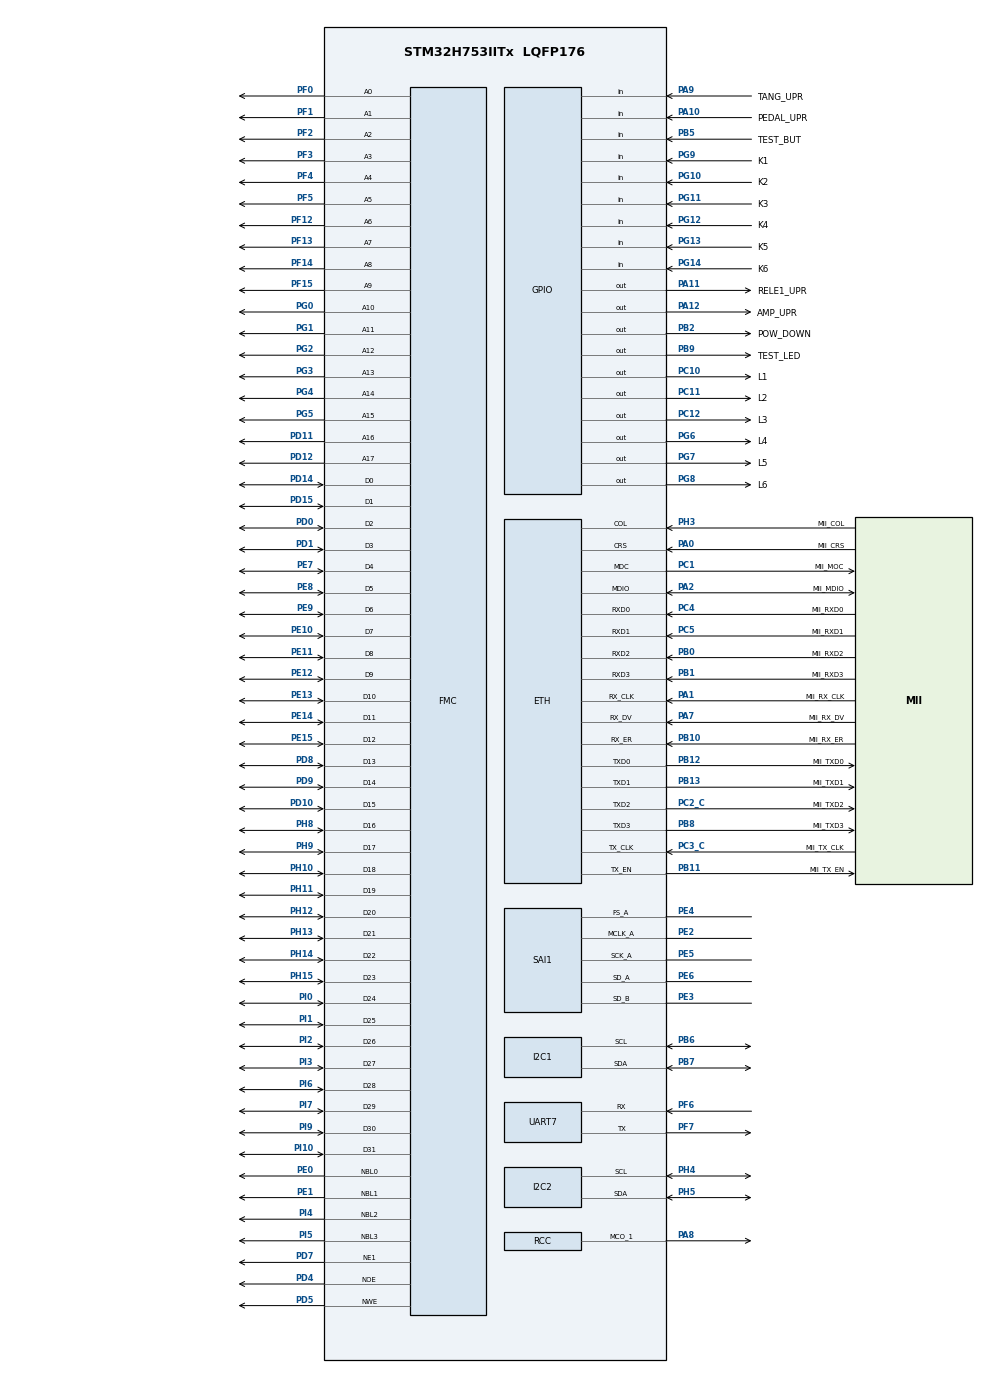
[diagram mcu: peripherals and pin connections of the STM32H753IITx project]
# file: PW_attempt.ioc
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CORTEX_M7.AccessPermission-Cortex_Memory_Protection_Unit_Region0_Settings=MPU_REGION_FULL_ACCESS
CORTEX_M7.AccessPermission-Cortex_Memory_Protection_Unit_Region1_Settings=MPU_REGION_FULL_ACCESS
CORTEX_M7.AccessPermission-Cortex_Memory_Protection_Unit_Region2_Settings=MPU_REGION_FULL_ACCESS
CORTEX_M7.BaseAddress-Cortex_Memory_Protection_Unit_Region0_Settings=30000000
CORTEX_M7.BaseAddress-Cortex_Memory_Protection_Unit_Region1_Settings=0x30000000
CORTEX_M7.BaseAddress-Cortex_Memory_Protection_Unit_Region2_Settings=0x30040000
CORTEX_M7.CPU_DCache=Enabled
CORTEX_M7.CPU_ICache=Enabled
CORTEX_M7.DisableExec-Cortex_Memory_Protection_Unit_Region0_Settings=MPU_INSTRUCTION_ACCESS_DISABLE
CORTEX_M7.DisableExec-Cortex_Memory_Protection_Unit_Region1_Settings=MPU_INSTRUCTION_ACCESS_DISABLE
CORTEX_M7.DisableExec-Cortex_Memory_Protection_Unit_Region2_Settings=MPU_INSTRUCTION_ACCESS_DISABLE
CORTEX_M7.Enable-Cortex_Memory_Protection_Unit_Region0_Settings=MPU_REGION_ENABLE
CORTEX_M7.Enable-Cortex_Memory_Protection_Unit_Region1_Settings=MPU_REGION_ENABLE
CORTEX_M7.Enable-Cortex_Memory_Protection_Unit_Region2_Settings=MPU_REGION_ENABLE
CORTEX_M7.IsBufferable-Cortex_Memory_Protection_Unit_Region0_Settings=MPU_ACCESS_NOT_BUFFERABLE
CORTEX_M7.IsBufferable-Cortex_Memory_Protection_Unit_Region1_Settings=MPU_ACCESS_BUFFERABLE
CORTEX_M7.IsCacheable-Cortex_Memory_Protection_Unit_Region1_Settings=MPU_ACCESS_NOT_CACHEABLE
CORTEX_M7.IsShareable-Cortex_Memory_Protection_Unit_Region0_Settings=MPU_ACCESS_NOT_SHAREABLE
CORTEX_M7.IsShareable-Cortex_Memory_Protection_Unit_Region1_Settings=MPU_ACCESS_SHAREABLE
CORTEX_M7.MPU_Control=MPU_PRIVILEGED_DEFAULT
CORTEX_M7.Size-Cortex_Memory_Protection_Unit_Region0_Settings=MPU_REGION_SIZE_256KB
CORTEX_M7.Size-Cortex_Memory_Protection_Unit_Region1_Settings=MPU_REGION_SIZE_256B
CORTEX_M7.Size-Cortex_Memory_Protection_Unit_Region2_Settings=MPU_REGION_SIZE_32KB
CORTEX_M7.TypeExtField-Cortex_Memory_Protection_Unit_Region0_Settings=MPU_TEX_LEVEL1
CORTEX_M7.TypeExtField-Cortex_Memory_Protection_Unit_Region2_Settings=MPU_TEX_LEVEL1
Dma.I2C1_RX.1.Direction=DMA_PERIPH_TO_MEMORY
Dma.I2C1_RX.1.EventEnable=DISABLE
Dma.I2C1_RX.1.FIFOMode=DMA_FIFOMODE_DISABLE
Dma.I2C1_RX.1.Instance=DMA2_Stream0
Dma.I2C1_RX.1.MemDataAlignment=DMA_MDATAALIGN_BYTE
Dma.I2C1_RX.1.MemInc=DMA_MINC_ENABLE
Dma.I2C1_RX.1.Mode=DMA_NORMAL
Dma.I2C1_RX.1.PeriphDataAlignment=DMA_PDATAALIGN_BYTE
Dma.I2C1_RX.1.PeriphInc=DMA_PINC_DISABLE
Dma.I2C1_RX.1.Polarity=HAL_DMAMUX_REQ_GEN_RISING
Dma.I2C1_RX.1.Priority=DMA_PRIORITY_HIGH
Dma.I2C1_RX.1.RequestNumber=1
Dma.I2C1_RX.1.SignalID=NONE
Dma.I2C1_RX.1.SyncEnable=DISABLE
Dma.I2C1_RX.1.SyncPolarity=HAL_DMAMUX_SYNC_NO_EVENT
Dma.I2C1_RX.1.SyncRequestNumber=1
Dma.I2C1_RX.1.SyncSignalID=NONE
Dma.I2C1_TX.2.Direction=DMA_MEMORY_TO_PERIPH
Dma.I2C1_TX.2.EventEnable=DISABLE
Dma.I2C1_TX.2.FIFOMode=DMA_FIFOMODE_DISABLE
Dma.I2C1_TX.2.Instance=DMA2_Stream1
Dma.I2C1_TX.2.MemDataAlignment=DMA_MDATAALIGN_BYTE
Dma.I2C1_TX.2.MemInc=DMA_MINC_ENABLE
Dma.I2C1_TX.2.Mode=DMA_NORMAL
Dma.I2C1_TX.2.PeriphDataAlignment=DMA_PDATAALIGN_BYTE
Dma.I2C1_TX.2.PeriphInc=DMA_PINC_DISABLE
Dma.I2C1_TX.2.Polarity=HAL_DMAMUX_REQ_GEN_RISING
Dma.I2C1_TX.2.Priority=DMA_PRIORITY_HIGH
Dma.I2C1_TX.2.RequestNumber=1
Dma.I2C1_TX.2.SignalID=NONE
Dma.I2C1_TX.2.SyncEnable=DISABLE
Dma.I2C1_TX.2.SyncPolarity=HAL_DMAMUX_SYNC_NO_EVENT
Dma.I2C1_TX.2.SyncRequestNumber=1
Dma.I2C1_TX.2.SyncSignalID=NONE
Dma.I2C2_RX.5.Direction=DMA_PERIPH_TO_MEMORY
Dma.I2C2_RX.5.EventEnable=DISABLE
Dma.I2C2_RX.5.FIFOMode=DMA_FIFOMODE_DISABLE
Dma.I2C2_RX.5.Instance=DMA1_Stream2
Dma.I2C2_RX.5.MemDataAlignment=DMA_MDATAALIGN_BYTE
Dma.I2C2_RX.5.MemInc=DMA_MINC_ENABLE
Dma.I2C2_RX.5.Mode=DMA_NORMAL
Dma.I2C2_RX.5.PeriphDataAlignment=DMA_PDATAALIGN_BYTE
Dma.I2C2_RX.5.PeriphInc=DMA_PINC_DISABLE
Dma.I2C2_RX.5.Polarity=HAL_DMAMUX_REQ_GEN_RISING
Dma.I2C2_RX.5.Priority=DMA_PRIORITY_LOW
Dma.I2C2_RX.5.RequestNumber=1
Dma.I2C2_RX.5.SignalID=NONE
Dma.I2C2_RX.5.SyncEnable=DISABLE
Dma.I2C2_RX.5.SyncPolarity=HAL_DMAMUX_SYNC_NO_EVENT
Dma.I2C2_RX.5.SyncRequestNumber=1
Dma.I2C2_RX.5.SyncSignalID=NONE
Dma.I2C2_TX.6.Direction=DMA_MEMORY_TO_PERIPH
Dma.I2C2_TX.6.EventEnable=DISABLE
Dma.I2C2_TX.6.FIFOMode=DMA_FIFOMODE_DISABLE
Dma.I2C2_TX.6.Instance=DMA1_Stream4
Dma.I2C2_TX.6.MemDataAlignment=DMA_MDATAALIGN_BYTE
Dma.I2C2_TX.6.MemInc=DMA_MINC_ENABLE
Dma.I2C2_TX.6.Mode=DMA_NORMAL
Dma.I2C2_TX.6.PeriphDataAlignment=DMA_PDATAALIGN_BYTE
Dma.I2C2_TX.6.PeriphInc=DMA_PINC_DISABLE
Dma.I2C2_TX.6.Polarity=HAL_DMAMUX_REQ_GEN_RISING
Dma.I2C2_TX.6.Priority=DMA_PRIORITY_LOW
Dma.I2C2_TX.6.RequestNumber=1
Dma.I2C2_TX.6.SignalID=NONE
Dma.I2C2_TX.6.SyncEnable=DISABLE
Dma.I2C2_TX.6.SyncPolarity=HAL_DMAMUX_SYNC_NO_EVENT
Dma.I2C2_TX.6.SyncRequestNumber=1
Dma.I2C2_TX.6.SyncSignalID=NONE
Dma.Request0=UART7_TX
Dma.Request1=I2C1_RX
Dma.Request2=I2C1_TX
Dma.Request3=SAI1_A
Dma.Request4=SAI1_B
Dma.Request5=I2C2_RX
Dma.Request6=I2C2_TX
Dma.SAI1_A.3.Direction=DMA_MEMORY_TO_PERIPH
Dma.SAI1_A.3.EventEnable=DISABLE
Dma.SAI1_A.3.FIFOMode=DMA_FIFOMODE_DISABLE
Dma.SAI1_A.3.Instance=DMA2_Stream3
Dma.SAI1_A.3.MemDataAlignment=DMA_MDATAALIGN_WORD
Dma.SAI1_A.3.MemInc=DMA_MINC_ENABLE
Dma.SAI1_A.3.Mode=DMA_NORMAL
Dma.SAI1_A.3.PeriphDataAlignment=DMA_PDATAALIGN_WORD
Dma.SAI1_A.3.PeriphInc=DMA_PINC_DISABLE
Dma.SAI1_A.3.Polarity=HAL_DMAMUX_REQ_GEN_RISING
Dma.SAI1_A.3.Priority=DMA_PRIORITY_LOW
Dma.SAI1_A.3.RequestNumber=1
Dma.SAI1_A.3.SignalID=NONE
Dma.SAI1_A.3.SyncEnable=DISABLE
Dma.SAI1_A.3.SyncPolarity=HAL_DMAMUX_SYNC_NO_EVENT
Dma.SAI1_A.3.SyncRequestNumber=1
Dma.SAI1_A.3.SyncSignalID=NONE
Dma.SAI1_B.4.Direction=DMA_PERIPH_TO_MEMORY
Dma.SAI1_B.4.EventEnable=DISABLE
Dma.SAI1_B.4.FIFOMode=DMA_FIFOMODE_DISABLE
Dma.SAI1_B.4.Instance=DMA2_Stream4
Dma.SAI1_B.4.MemDataAlignment=DMA_MDATAALIGN_WORD
Dma.SAI1_B.4.MemInc=DMA_MINC_ENABLE
Dma.SAI1_B.4.Mode=DMA_NORMAL
Dma.SAI1_B.4.PeriphDataAlignment=DMA_PDATAALIGN_WORD
Dma.SAI1_B.4.PeriphInc=DMA_PINC_DISABLE
Dma.SAI1_B.4.Polarity=HAL_DMAMUX_REQ_GEN_RISING
Dma.SAI1_B.4.Priority=DMA_PRIORITY_LOW
Dma.SAI1_B.4.RequestNumber=1
Dma.SAI1_B.4.SignalID=NONE
Dma.SAI1_B.4.SyncEnable=DISABLE
Dma.SAI1_B.4.SyncPolarity=HAL_DMAMUX_SYNC_NO_EVENT
Dma.SAI1_B.4.SyncRequestNumber=1
Dma.SAI1_B.4.SyncSignalID=NONE
Dma.UART7_TX.0.Direction=DMA_MEMORY_TO_PERIPH
Dma.UART7_TX.0.EventEnable=DISABLE
Dma.UART7_TX.0.FIFOMode=DMA_FIFOMODE_DISABLE
Dma.UART7_TX.0.Instance=DMA1_Stream1
Dma.UART7_TX.0.MemDataAlignment=DMA_MDATAALIGN_BYTE
Dma.UART7_TX.0.MemInc=DMA_MINC_ENABLE
Dma.UART7_TX.0.Mode=DMA_NORMAL
Dma.UART7_TX.0.PeriphDataAlignment=DMA_PDATAALIGN_BYTE
Dma.UART7_TX.0.PeriphInc=DMA_PINC_DISABLE
Dma.UART7_TX.0.Polarity=HAL_DMAMUX_REQ_GEN_RISING
Dma.UART7_TX.0.Priority=DMA_PRIORITY_VERY_HIGH
Dma.UART7_TX.0.RequestNumber=1
Dma.UART7_TX.0.SignalID=NONE
Dma.UART7_TX.0.SyncEnable=DISABLE
Dma.UART7_TX.0.SyncPolarity=HAL_DMAMUX_SYNC_NO_EVENT
Dma.UART7_TX.0.SyncRequestNumber=1
Dma.UART7_TX.0.SyncSignalID=NONE
ETH.MACAddr=00\:80\:E1\:00\:00\:00
ETH.MediaInterface=HAL_ETH_MII_MODE
ETH.RxBuffAddress=0x30000200
ETH.RxBuffLen=1524
ETH.RxDescAddress=0x30000000
ETH.TxDescAddress=0x30000060
FREERTOS.MEMORY_ALLOCATION=0
FREERTOS.Tasks01=defaultTask,0,256,StartDefaultTask,Default,NULL,Dynamic,NULL,NULL;Test_Led_Task,-2,256,Test_Led_Task_,Default,NULL,Dynamic,NULL,NULL;LEDS_1_2_3_TEST,-2,256,LEDS_1_2_3_TEST_,Default,NULL,Dynamic,NULL,NULL;LEDS_4_5_6_TEST,-2,256,LEDS_4_5_6_TEST_,Default,NULL,Dynamic,NULL,NULL;KEYS_TEST_TASK,-2,256,KEYS_TEST_TASK_,Default,NULL,Dynamic,NULL,NULL;EEPROM_Tests,-2,256,EEPROM_Tests_,Default,NULL,Dynamic,NULL,NULL
FREERTOS.configMINIMAL_STACK_SIZE=256
FREERTOS.configTOTAL_HEAP_SIZE=32768
FREERTOS.configUSE_TIMERS=1
I2C1.Timing=0x307075B1
I2C2.Timing=0x307075B1
LWIP.BSP.number=1
LWIP.CMSIS_VERSION-Enabled=1
LWIP.GATEWAY_ADDRESS=000.000.000.000
LWIP.IP_ADDRESS=192.168.000.101
LWIP.LWIP_DHCP=0
LWIP.LWIP_DNS=0
LWIP.LWIP_ICMP=1
LWIP.LWIP_NETIF_LOOPBACK=1
LWIP.LWIP_RAM_HEAP_POINTER=0x30040000
LWIP.LWIP_STATS=1
LWIP.LWIP_STATS_DISPLAY=1
LWIP.LWIP_TCP=0
LWIP.MEMP_NUM_PBUF=20
LWIP.MEM_SIZE=32744
LWIP.NETMASK_ADDRESS=255.255.255.000
LWIP.PPPOE_SUPPORT=0
LWIP.SYS_LIGHTWEIGHT_PROT=0
LWIP.Version=v2.1.2_Cube
LWIP0.BSP.STBoard=false
LWIP0.BSP.api=BSP_COMPONENT_DRIVER
LWIP0.BSP.component=LAN8742
LWIP0.BSP.i2caddr=0
LWIP0.BSP.instance=LAN8742
LWIP0.BSP.name=Driver_PHY
LWIP0.BSP.solution=LAN8742
Mcu.Family=STM32H7
Mcu.Name=STM32H753IITx
Mcu.Package=LQFP176
NVIC.DMA1_Stream1_IRQn=true\:5\:0\:false\:false\:true\:true\:false\:true
NVIC.DMA1_Stream2_IRQn=true\:5\:0\:false\:false\:true\:false\:false\:true
NVIC.DMA1_Stream4_IRQn=true\:5\:0\:false\:false\:true\:true\:false\:true
NVIC.DMA2_Stream0_IRQn=true\:5\:0\:false\:false\:true\:true\:false\:true
NVIC.DMA2_Stream1_IRQn=true\:5\:0\:false\:false\:true\:true\:false\:true
NVIC.DMA2_Stream3_IRQn=true\:5\:0\:false\:false\:true\:true\:false\:true
NVIC.DMA2_Stream4_IRQn=true\:5\:0\:false\:false\:true\:true\:false\:true
NVIC.ETH_IRQn=true\:8\:0\:true\:false\:true\:false\:true\:true
NVIC.I2C2_ER_IRQn=true\:5\:0\:false\:false\:true\:true\:true\:true
NVIC.I2C2_EV_IRQn=true\:5\:0\:false\:false\:true\:true\:true\:true
NVIC.PriorityGroup=NVIC_PRIORITYGROUP_4
NVIC.SAI1_IRQn=true\:5\:0\:false\:false\:true\:true\:true\:true
NVIC.TIM1_UP_IRQn=true\:15\:0\:false\:false\:true\:false\:false\:true
NVIC.TIM3_IRQn=true\:5\:0\:false\:false\:true\:true\:true\:true
NVIC.TimeBase=TIM1_UP_IRQn
NVIC.TimeBaseIP=TIM1
NVIC.UART7_IRQn=true\:5\:0\:false\:false\:true\:true\:true\:true
PA0.GPIO_Label=MII_CRS
PA0.GPIO_Speed=GPIO_SPEED_FREQ_LOW
PA0.Mode=MII
PA0.Signal=ETH_CRS
PA1.GPIO_Label=MII_RX_CLK
PA1.GPIO_Speed=GPIO_SPEED_FREQ_LOW
PA1.Mode=MII
PA1.Signal=ETH_RX_CLK
PA10.GPIO_Label=PEDAL_UPR
PA10.Signal=GPIO_Input
PA11.GPIO_Label=RELE1_UPR
PA11.Signal=GPIO_Output
PA12.GPIO_Label=AMP_UPR
PA12.Signal=GPIO_Output
PA13\ (JTMS/SWDIO).Mode=JTAG_5_pins
PA13\ (JTMS/SWDIO).Signal=DEBUG_JTMS-SWDIO
PA14\ (JTCK/SWCLK).Mode=JTAG_5_pins
PA14\ (JTCK/SWCLK).Signal=DEBUG_JTCK-SWCLK
PA15\ (JTDI).Mode=JTAG_5_pins
PA15\ (JTDI).Signal=DEBUG_JTDI
PA2.GPIO_Label=MII_MDIO
PA2.GPIO_Speed=GPIO_SPEED_FREQ_LOW
PA2.Mode=MII
PA2.Signal=ETH_MDIO
PA7.GPIO_Label=MII_RX_DV
PA7.GPIO_Speed=GPIO_SPEED_FREQ_LOW
PA7.Mode=MII
PA7.Signal=ETH_RX_DV
PA8.GPIO_PuPd=GPIO_PULLUP
PA8.Mode=Clock-out-1
PA8.Signal=RCC_MCO_1
PA9.GPIO_Label=TANG_UPR
PA9.Signal=GPIO_Input
PB0.GPIO_Label=MII_RXD2
PB0.GPIO_Speed=GPIO_SPEED_FREQ_LOW
PB0.Mode=MII
PB0.Signal=ETH_RXD2
PB1.GPIO_Label=MII_RXD3
PB1.GPIO_Speed=GPIO_SPEED_FREQ_LOW
PB1.Mode=MII
PB1.Signal=ETH_RXD3
PB10.GPIO_Label=MII_RX_ER
PB10.GPIO_Speed=GPIO_SPEED_FREQ_LOW
PB10.Mode=Activate Rx Err signal
PB10.Signal=ETH_RX_ER
PB11.GPIO_Label=MII_TX_EN
PB11.GPIO_Speed=GPIO_SPEED_FREQ_LOW
PB11.Mode=MII
PB11.Signal=ETH_TX_EN
PB12.GPIO_Label=MII_TXD0
PB12.GPIO_Speed=GPIO_SPEED_FREQ_LOW
PB12.Mode=MII
PB12.Signal=ETH_TXD0
PB13.GPIO_Label=MII_TXD1
PB13.GPIO_Speed=GPIO_SPEED_FREQ_LOW
PB13.Mode=MII
PB13.Signal=ETH_TXD1
PB2.GPIO_Label=POW_DOWN
PB2.PinState=GPIO_PIN_SET
PB2.Signal=GPIO_Output
PB3\ (JTDO/TRACESWO).Mode=JTAG_5_pins
PB3\ (JTDO/TRACESWO).Signal=DEBUG_JTDO-SWO
PB4\ (NJTRST).Mode=JTAG_5_pins
PB4\ (NJTRST).Signal=DEBUG_JTRST
PB5.GPIO_Label=TEST_BUT
PB5.Signal=GPIO_Input
PB6.GPIO_Pu=GPIO_PULLUP
PB6.GPIO_Speed=GPIO_SPEED_FREQ_HIGH
PB6.Mode=I2C
PB6.Signal=I2C1_SCL
PB7.GPIO_Pu=GPIO_PULLUP
PB7.GPIO_Speed=GPIO_SPEED_FREQ_HIGH
PB7.Mode=I2C
PB7.Signal=I2C1_SDA
PB8.GPIO_Label=MII_TXD3
PB8.GPIO_Speed=GPIO_SPEED_FREQ_LOW
PB8.Mode=MII
PB8.Signal=ETH_TXD3
PB9.GPIO_Label=TEST_LED
PB9.PinState=GPIO_PIN_SET
PB9.Signal=GPIO_Output
PC1.GPIO_Label=MII_MOC
PC1.GPIO_Speed=GPIO_SPEED_FREQ_LOW
PC1.Mode=MII
PC1.Signal=ETH_MDC
PC10.GPIO_Label=L1
PC10.Signal=GPIO_Output
PC11.GPIO_Label=L2
PC11.Signal=GPIO_Output
PC12.GPIO_Label=L3
PC12.Signal=GPIO_Output
PC2_C.GPIO_Label=MII_TXD2
PC2_C.GPIO_Speed=GPIO_SPEED_FREQ_LOW
PC2_C.Mode=MII
PC2_C.Signal=ETH_TXD2
PC3_C.GPIO_Label=MII_TX_CLK
PC3_C.GPIO_Speed=GPIO_SPEED_FREQ_LOW
PC3_C.Mode=MII
PC3_C.Signal=ETH_TX_CLK
PC4.GPIO_Label=MII_RXD0
PC4.GPIO_Speed=GPIO_SPEED_FREQ_LOW
PC4.Mode=MII
PC4.Signal=ETH_RXD0
PC5.GPIO_Label=MII_RXD1
PC5.GPIO_Speed=GPIO_SPEED_FREQ_LOW
PC5.Mode=MII
PC5.Signal=ETH_RXD1
PD0.Signal=FMC_D2_DA2
PD1.Signal=FMC_D3_DA3
PD10.Signal=FMC_D15_DA15
PD11.Signal=FMC_A16_CLE
PD12.Signal=FMC_A17_ALE
PD14.Signal=FMC_D0_DA0
PD15.Signal=FMC_D1_DA1
PD4.Signal=FMC_NOE
PD5.Signal=FMC_NWE
PD7.Mode=NorPsramChipSelect1_1
PD7.Signal=FMC_NE1
PD8.Signal=FMC_D13_DA13
PD9.Signal=FMC_D14_DA14
PE0.Signal=FMC_NBL0
PE1.Signal=FMC_NBL1
PE10.Signal=FMC_D7_DA7
PE11.Signal=FMC_D8_DA8
PE12.Signal=FMC_D9_DA9
PE13.Signal=FMC_D10_DA10
PE14.Signal=FMC_D11_DA11
PE15.Signal=FMC_D12_DA12
PE2.GPIO_Speed=GPIO_SPEED_FREQ_VERY_HIGH
PE2.Mode=SAI_A_MasterWithClock
PE2.Signal=SAI1_MCLK_A
PE3.GPIO_Speed=GPIO_SPEED_FREQ_VERY_HIGH
PE3.Mode=SAI_B_SyncSlave
PE3.Signal=SAI1_SD_B
PE4.GPIO_Speed=GPIO_SPEED_FREQ_VERY_HIGH
PE4.Mode=SAI_A_MasterWithClock
PE4.Signal=SAI1_FS_A
PE5.GPIO_Speed=GPIO_SPEED_FREQ_VERY_HIGH
PE5.Mode=SAI_A_MasterWithClock
PE5.Signal=SAI1_SCK_A
PE6.GPIO_Speed=GPIO_SPEED_FREQ_VERY_HIGH
PE6.Mode=SAI_A_MasterWithClock
PE6.Signal=SAI1_SD_A
PE7.Signal=FMC_D4_DA4
PE8.Signal=FMC_D5_DA5
PE9.Signal=FMC_D6_DA6
PF0.Signal=FMC_A0
PF1.Signal=FMC_A1
PF12.Signal=FMC_A6
PF13.Signal=FMC_A7
PF14.Signal=FMC_A8
PF15.Signal=FMC_A9
PF2.Signal=FMC_A2
PF3.Signal=FMC_A3
PF4.Signal=FMC_A4
PF5.Signal=FMC_A5
PF6.GPIO_Speed=GPIO_SPEED_FREQ_LOW
PF6.Mode=Asynchronous
PF6.Signal=UART7_RX
PF7.GPIO_Speed=GPIO_SPEED_FREQ_LOW
PF7.Mode=Asynchronous
PF7.Signal=UART7_TX
PG0.Signal=FMC_A10
PG1.Signal=FMC_A11
PG10.GPIO_Label=K2
PG10.Signal=GPIO_Input
PG11.GPIO_Label=K3
PG11.Signal=GPIO_Input
PG12.GPIO_Label=K4
PG12.Signal=GPIO_Input
PG13.GPIO_Label=K5
PG13.Signal=GPIO_Input
PG14.GPIO_Label=K6
PG14.Signal=GPIO_Input
PG2.Signal=FMC_A12
PG3.Signal=FMC_A13
PG4.Signal=FMC_A14_BA0
PG5.Signal=FMC_A15_BA1
PG6.GPIO_Label=L4
PG6.Signal=GPIO_Output
PG7.GPIO_Label=L5
PG7.Signal=GPIO_Output
PG8.GPIO_Label=L6
PG8.Signal=GPIO_Output
PG9.GPIO_Label=K1
PG9.Signal=GPIO_Input
PH0-OSC_IN\ (PH0).Mode=HSE-External-Oscillator
PH0-OSC_IN\ (PH0).Signal=RCC_OSC_IN
PH1-OSC_OUT\ (PH1).Mode=HSE-External-Oscillator
PH1-OSC_OUT\ (PH1).Signal=RCC_OSC_OUT
PH10.Signal=FMC_D18
PH11.Signal=FMC_D19
PH12.Signal=FMC_D20
PH13.Signal=FMC_D21
PH14.Signal=FMC_D22
PH15.Signal=FMC_D23
PH3.GPIO_Label=MII_COL
PH3.GPIO_Speed=GPIO_SPEED_FREQ_LOW
PH3.Mode=MII
PH3.Signal=ETH_COL
PH4.GPIO_Pu=GPIO_PULLUP
PH4.GPIO_Speed=GPIO_SPEED_FREQ_HIGH
PH4.Mode=I2C
PH4.Signal=I2C2_SCL
PH5.GPIO_Pu=GPIO_PULLUP
PH5.GPIO_Speed=GPIO_SPEED_FREQ_HIGH
PH5.Mode=I2C
PH5.Signal=I2C2_SDA
PH8.Signal=FMC_D16
PH9.Signal=FMC_D17
PI0.Signal=FMC_D24
PI1.Signal=FMC_D25
PI10.Signal=FMC_D31
PI2.Signal=FMC_D26
PI3.Signal=FMC_D27
PI4.Signal=FMC_NBL2
PI5.Signal=FMC_NBL3
PI6.Signal=FMC_D28
PI7.Signal=FMC_D29
PI9.Signal=FMC_D30
ProjectManager.HeapSize=0x200
ProjectManager.StackSize=0x400
ProjectManager.TargetToolchain=STM32CubeIDE
RCC.ADCFreq_Value=4096000
RCC.APB1Freq_Value=120000000
RCC.APB2Freq_Value=120000000
RCC.APB3Freq_Value=120000000
RCC.APB4Freq_Value=120000000
RCC.CKPERSourceSelection=RCC_CLKPSOURCE_HSE
RCC.CortexFreq_Value=480000000
RCC.D1PPRE=RCC_APB3_DIV2
RCC.D2PPRE1=RCC_APB1_DIV2
RCC.D2PPRE2=RCC_APB2_DIV2
RCC.D3PPRE=RCC_APB4_DIV2
RCC.DIVM1=10
RCC.DIVM2=25
RCC.DIVM3=25
RCC.DIVN1=384
RCC.DIVN2=512
RCC.DIVN3=150
RCC.DIVP2=125
RCC.DIVP3=1
RCC.DIVQ1=10
RCC.DIVQ2=125
RCC.DIVQ3=1
RCC.DIVR1=4
RCC.DIVR2=125
RCC.DIVR3=1
RCC.EnbaleCSS=true
RCC.FMCCLockSelection=RCC_FMCCLKSOURCE_PLL
RCC.HCLKFreq_Value=240000000
RCC.HPRE=RCC_HCLK_DIV2
RCC.PLL2FRACN=0
RCC.PLL3FRACN=0
RCC.PLLFRACN=0
RCC.PLLSourceVirtual=RCC_PLLSOURCE_HSE
RCC.RCC_MCO1Source=RCC_MCO1SOURCE_HSE
RCC.SAI1CLockSelection=RCC_SAI1CLKSOURCE_PLL2
RCC.SYSCLKFreq_VALUE=480000000
RCC.SYSCLKSource=RCC_SYSCLKSOURCE_PLLCLK
RCC.USBFreq_Value=96000000
SAI1.AudioFrequency-SAI_A_MasterWithClock=SAI_AUDIO_FREQUENCY_16K
SAI1.ErrorAudioFreq-SAI_A_MasterWithClock=0.0 %
SAI1.InitProtocol-SAI_A_MasterWithClock=Enable
SAI1.InitProtocol-SAI_B_SyncSlave=Enable
SAI1.Instance-SAI_A_MasterWithClock=SAI$Index_Block_A
SAI1.Instance-SAI_B_SyncSlave=SAI$Index_Block_B
SAI1.MClockEnable-SAI_A_MasterWithClock=SAI_MASTERCLOCK_ENABLE
SAI1.RealAudioFreq-SAI_A_MasterWithClock=16.0 KHz
SAI1.VirtualMode-SAI_A_MasterWithClock=VM_MASTER
SAI1.VirtualMode-SAI_B_SyncSlave=VM_SLAVE
SAI1.VirtualProtocol-SAI_A_BASIC=VM_BASIC_PROTOCOL
SAI1.VirtualProtocol-SAI_B_BASIC=VM_BASIC_PROTOCOL
SH.FMC_A0.0=FMC_A0,18b-a1
SH.FMC_A1.0=FMC_A1,18b-a1
SH.FMC_A10.0=FMC_A10,18b-a1
SH.FMC_A11.0=FMC_A11,18b-a1
SH.FMC_A12.0=FMC_A12,18b-a1
SH.FMC_A13.0=FMC_A13,18b-a1
SH.FMC_A14_BA0.0=FMC_A14,18b-a1
SH.FMC_A15_BA1.0=FMC_A15,18b-a1
SH.FMC_A16_CLE.0=FMC_A16,18b-a1
SH.FMC_A17_ALE.0=FMC_A17,18b-a1
SH.FMC_A2.0=FMC_A2,18b-a1
SH.FMC_A3.0=FMC_A3,18b-a1
SH.FMC_A4.0=FMC_A4,18b-a1
SH.FMC_A5.0=FMC_A5,18b-a1
SH.FMC_A6.0=FMC_A6,18b-a1
SH.FMC_A7.0=FMC_A7,18b-a1
SH.FMC_A8.0=FMC_A8,18b-a1
SH.FMC_A9.0=FMC_A9,18b-a1
SH.FMC_D0_DA0.0=FMC_D0,32b-d1
SH.FMC_D10_DA10.0=FMC_D10,32b-d1
SH.FMC_D11_DA11.0=FMC_D11,32b-d1
SH.FMC_D12_DA12.0=FMC_D12,32b-d1
SH.FMC_D13_DA13.0=FMC_D13,32b-d1
SH.FMC_D14_DA14.0=FMC_D14,32b-d1
SH.FMC_D15_DA15.0=FMC_D15,32b-d1
SH.FMC_D16.0=FMC_D16,32b-d1
SH.FMC_D17.0=FMC_D17,32b-d1
SH.FMC_D18.0=FMC_D18,32b-d1
SH.FMC_D19.0=FMC_D19,32b-d1
SH.FMC_D1_DA1.0=FMC_D1,32b-d1
SH.FMC_D20.0=FMC_D20,32b-d1
SH.FMC_D21.0=FMC_D21,32b-d1
SH.FMC_D22.0=FMC_D22,32b-d1
SH.FMC_D23.0=FMC_D23,32b-d1
SH.FMC_D24.0=FMC_D24,32b-d1
SH.FMC_D25.0=FMC_D25,32b-d1
SH.FMC_D26.0=FMC_D26,32b-d1
SH.FMC_D27.0=FMC_D27,32b-d1
SH.FMC_D28.0=FMC_D28,32b-d1
SH.FMC_D29.0=FMC_D29,32b-d1
SH.FMC_D2_DA2.0=FMC_D2,32b-d1
SH.FMC_D30.0=FMC_D30,32b-d1
SH.FMC_D31.0=FMC_D31,32b-d1
SH.FMC_D3_DA3.0=FMC_D3,32b-d1
SH.FMC_D4_DA4.0=FMC_D4,32b-d1
SH.FMC_D5_DA5.0=FMC_D5,32b-d1
SH.FMC_D6_DA6.0=FMC_D6,32b-d1
SH.FMC_D7_DA7.0=FMC_D7,32b-d1
SH.FMC_D8_DA8.0=FMC_D8,32b-d1
SH.FMC_D9_DA9.0=FMC_D9,32b-d1
SH.FMC_NBL0.0=FMC_NBL0,4ByteEnable1
SH.FMC_NBL1.0=FMC_NBL1,4ByteEnable1
SH.FMC_NBL2.0=FMC_NBL2,4ByteEnable1
SH.FMC_NBL3.0=FMC_NBL3,4ByteEnable1
SH.FMC_NOE.0=FMC_NOE,Sram1
SH.FMC_NWE.0=FMC_NWE,Sram1
TIM3.Period=15000
UART7.FIFOMode=FIFOMODE_ENABLE
UART7.RXFIFOThreshold=RXFIFO_THRESHOLD_HALFFULL
UART7.TXFIFOThreshold=TXFIFO_THRESHOLD_HALFFULL
VP_FREERTOS_VS_CMSIS_V1.Mode=CMSIS_V1
VP_LWIP_VS_Enabled.Mode=Enabled
VP_RNG_VS_RNG.Mode=RNG_Activate
VP_RTC_VS_RTC_Activate.Mode=RTC_Enabled
VP_RTC_VS_RTC_Calendar.Mode=RTC_Calendar
VP_SAI1_VP_$IpInstance_SAIA_SAI_BASIC.Mode=SAI_A_BASIC
VP_SAI1_VP_$IpInstance_SAIB_SAI_BASIC.Mode=SAI_B_BASIC
VP_SYS_VS_tim1.Mode=TIM1
VP_TIM3_VS_ClockSourceINT.Mode=Internal
board=custom

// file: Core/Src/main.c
/* USER CODE BEGIN Header */
/**
  ******************************************************************************
  * @file           : main.c
  * @brief          : Main program body
  ******************************************************************************
  * @attention
  *
  * Copyright (c) 2022 STMicroelectronics.
  * All rights reserved.
  *
  * This software is licensed under terms that can be found in the LICENSE file
  * in the root directory of this software component.
  * If no LICENSE file comes with this software, it is provided AS-IS.
  *
  ******************************************************************************
  */
/* USER CODE END Header */
#include "main.h"
#include "cmsis_os.h"
#include "lwip.h"

/* USER CODE BEGIN Includes */

#include <string.h>
#include "rs232.h"
#include "rs232_printf.h"
#include "i2ceeprom.h"
#include "fsforeeprom.h"
#include "dp83848.h"
#include "lwip/udp.h"
#define UDP_SERVER_PORT    7
#define UDP_CLIENT_PORT    7

/* USER CODE END Includes */

/* USER CODE BEGIN PM */

extern struct netif gnetif;
extern DP83848_Object_t DP83848;

void ethernet_link_check_state(struct netif *netif)
{
  ETH_MACConfigTypeDef MACConf;
  int32_t PHYLinkState;
  uint32_t linkchanged = 0, speed = 0, duplex =0;

  PHYLinkState = DP83848_GetLinkState(&DP83848);

  if(netif_is_link_up(netif) && (PHYLinkState <= DP83848_STATUS_LINK_DOWN))
  {
    HAL_ETH_Stop(&heth);
    netif_set_down(netif);
    netif_set_link_down(netif);
  }
  else if(!netif_is_link_up(netif) && (PHYLinkState > DP83848_STATUS_LINK_DOWN))
  {
    switch (PHYLinkState)
    {
    case DP83848_STATUS_100MBITS_FULLDUPLEX:
      duplex = ETH_FULLDUPLEX_MODE;
      speed = ETH_SPEED_100M;
      linkchanged = 1;
      break;
    case DP83848_STATUS_100MBITS_HALFDUPLEX:
      duplex = ETH_HALFDUPLEX_MODE;
      speed = ETH_SPEED_100M;
      linkchanged = 1;
      break;
    case DP83848_STATUS_10MBITS_FULLDUPLEX:
      duplex = ETH_FULLDUPLEX_MODE;
      speed = ETH_SPEED_10M;
      linkchanged = 1;
      break;
    case DP83848_STATUS_10MBITS_HALFDUPLEX:
      duplex = ETH_HALFDUPLEX_MODE;
      speed = ETH_SPEED_10M;
      linkchanged = 1;
      break;
    default:
      break;
    }

    if(linkchanged)
    {
      /* Get MAC Config MAC */
      HAL_ETH_GetMACConfig(&heth, &MACConf);
      MACConf.DuplexMode = duplex;
      MACConf.Speed = speed;
      HAL_ETH_SetMACConfig(&heth, &MACConf);

      HAL_ETH_Start(&heth);
      netif_set_up(netif);
      netif_set_link_up(netif);
    }
  }

}

uint32_t EthernetLinkTimer;
void Ethernet_Link_Periodic_Handle(struct netif *netif)
{
  /* Ethernet Link every 100ms */
  if (HAL_GetTick() - EthernetLinkTimer >= 100)
  {
    EthernetLinkTimer = HAL_GetTick();
    ethernet_link_check_state(netif);
  }
}

/* USER CODE END PM */

I2C_HandleTypeDef hi2c1;
I2C_HandleTypeDef hi2c2;
DMA_HandleTypeDef hdma_i2c1_rx;
DMA_HandleTypeDef hdma_i2c1_tx;
DMA_HandleTypeDef hdma_i2c2_rx;
DMA_HandleTypeDef hdma_i2c2_tx;

RNG_HandleTypeDef hrng;

RTC_HandleTypeDef hrtc;

SAI_HandleTypeDef hsai_BlockA1;
SAI_HandleTypeDef hsai_BlockB1;
DMA_HandleTypeDef hdma_sai1_a;
DMA_HandleTypeDef hdma_sai1_b;

TIM_HandleTypeDef htim3;

UART_HandleTypeDef huart7;
DMA_HandleTypeDef hdma_uart7_tx;

SRAM_HandleTypeDef hsram1;

osThreadId defaultTaskHandle;
osThreadId Test_Led_TaskHandle;
osThreadId LEDS_1_2_3_TESTHandle;
osThreadId LEDS_4_5_6_TESTHandle;
osThreadId KEYS_TEST_TASKHandle;
osThreadId EEPROM_TestsHandle;

void SystemClock_Config(void);
void PeriphCommonClock_Config(void);
static void MPU_Config(void);
static void MX_GPIO_Init(void);
static void MX_UART7_Init(void);
static void MX_DMA_Init(void);
static void MX_SAI1_Init(void);
static void MX_I2C1_Init(void);
static void MX_RTC_Init(void);
static void MX_RNG_Init(void);
static void MX_FMC_Init(void);
static void MX_I2C2_Init(void);
static void MX_TIM3_Init(void);
void StartDefaultTask(void const * argument);
void Test_Led_Task_(void const * argument);
void LEDS_1_2_3_TEST_(void const * argument);
void LEDS_4_5_6_TEST_(void const * argument);
void KEYS_TEST_TASK_(void const * argument);
void EEPROM_Tests_(void const * argument);

int main(void)
{
  /* USER CODE BEGIN 1 */
//#define LWIP_RAM_HEAP_POINTER (0x30044000)
  /* USER CODE END 1 */

  /* MPU Configuration--------------------------------------------------------*/
  MPU_Config();

  /* Enable I-Cache---------------------------------------------------------*/
  SCB_EnableICache();

  /* Enable D-Cache---------------------------------------------------------*/
  SCB_EnableDCache();

  /* MCU Configuration--------------------------------------------------------*/

  /* Reset of all peripherals, Initializes the Flash interface and the Systick. */
  HAL_Init();

  /* Configure the system clock */
  SystemClock_Config();

/* Configure the peripherals common clocks */
  PeriphCommonClock_Config();

  /* Initialize all configured peripherals */
  MX_GPIO_Init();
  MX_UART7_Init();
  MX_DMA_Init();
  MX_SAI1_Init();
  MX_I2C1_Init();
  MX_RTC_Init();
  MX_RNG_Init();
  MX_FMC_Init();
  MX_I2C2_Init();
  MX_TIM3_Init();
  /* USER CODE BEGIN 2 */

    littleFsInit();

  /* USER CODE END 2 */

  /* Create the thread(s) */
  /* definition and creation of defaultTask */
  osThreadDef(defaultTask, StartDefaultTask, osPriorityNormal, 0, 256);
  defaultTaskHandle = osThreadCreate(osThread(defaultTask), NULL);

  /* definition and creation of Test_Led_Task */
  osThreadDef(Test_Led_Task, Test_Led_Task_, osPriorityLow, 0, 256);
  Test_Led_TaskHandle = osThreadCreate(osThread(Test_Led_Task), NULL);

  /* definition and creation of LEDS_1_2_3_TEST */
  osThreadDef(LEDS_1_2_3_TEST, LEDS_1_2_3_TEST_, osPriorityLow, 0, 256);
  LEDS_1_2_3_TESTHandle = osThreadCreate(osThread(LEDS_1_2_3_TEST), NULL);

  /* definition and creation of LEDS_4_5_6_TEST */
  osThreadDef(LEDS_4_5_6_TEST, LEDS_4_5_6_TEST_, osPriorityLow, 0, 256);
  LEDS_4_5_6_TESTHandle = osThreadCreate(osThread(LEDS_4_5_6_TEST), NULL);

  /* definition and creation of KEYS_TEST_TASK */
  osThreadDef(KEYS_TEST_TASK, KEYS_TEST_TASK_, osPriorityLow, 0, 256);
  KEYS_TEST_TASKHandle = osThreadCreate(osThread(KEYS_TEST_TASK), NULL);

  /* definition and creation of EEPROM_Tests */
  osThreadDef(EEPROM_Tests, EEPROM_Tests_, osPriorityLow, 0, 256);
  EEPROM_TestsHandle = osThreadCreate(osThread(EEPROM_Tests), NULL);

  /* Start scheduler */
  osKernelStart();

  /* We should never get here as control is now taken by the scheduler */
  /* Infinite loop */
  while (1)
  {

  }
}

void SystemClock_Config(void)
{
  RCC_OscInitTypeDef RCC_OscInitStruct = {0};
  RCC_ClkInitTypeDef RCC_ClkInitStruct = {0};

  /** Supply configuration update enable
  */
  HAL_PWREx_ConfigSupply(PWR_LDO_SUPPLY);
  /** Configure the main internal regulator output voltage
  */
  __HAL_PWR_VOLTAGESCALING_CONFIG(PWR_REGULATOR_VOLTAGE_SCALE0);

  while(!__HAL_PWR_GET_FLAG(PWR_FLAG_VOSRDY)) {}
  /** Macro to configure the PLL clock source
  */
  __HAL_RCC_PLL_PLLSOURCE_CONFIG(RCC_PLLSOURCE_HSE);
  /** Initializes the RCC Oscillators according to the specified parameters
  * in the RCC_OscInitTypeDef structure.
  */
  RCC_OscInitStruct.OscillatorType = RCC_OSCILLATORTYPE_HSI48|RCC_OSCILLATORTYPE_LSI
                              |RCC_OSCILLATORTYPE_HSE;
  RCC_OscInitStruct.HSEState = RCC_HSE_ON;
  RCC_OscInitStruct.LSIState = RCC_LSI_ON;
  RCC_OscInitStruct.HSI48State = RCC_HSI48_ON;
  RCC_OscInitStruct.PLL.PLLState = RCC_PLL_ON;
  RCC_OscInitStruct.PLL.PLLSource = RCC_PLLSOURCE_HSE;
  RCC_OscInitStruct.PLL.PLLM = 10;
  RCC_OscInitStruct.PLL.PLLN = 384;
  RCC_OscInitStruct.PLL.PLLP = 2;
  RCC_OscInitStruct.PLL.PLLQ = 10;
  RCC_OscInitStruct.PLL.PLLR = 4;
  RCC_OscInitStruct.PLL.PLLRGE = RCC_PLL1VCIRANGE_1;
  RCC_OscInitStruct.PLL.PLLVCOSEL = RCC_PLL1VCOWIDE;
  RCC_OscInitStruct.PLL.PLLFRACN = 0;
  if (HAL_RCC_OscConfig(&RCC_OscInitStruct) != HAL_OK)
  {
    Error_Handler();
  }
  /** Initializes the CPU, AHB and APB buses clocks
  */
  RCC_ClkInitStruct.ClockType = RCC_CLOCKTYPE_HCLK|RCC_CLOCKTYPE_SYSCLK
                              |RCC_CLOCKTYPE_PCLK1|RCC_CLOCKTYPE_PCLK2
                              |RCC_CLOCKTYPE_D3PCLK1|RCC_CLOCKTYPE_D1PCLK1;
  RCC_ClkInitStruct.SYSCLKSource = RCC_SYSCLKSOURCE_PLLCLK;
  RCC_ClkInitStruct.SYSCLKDivider = RCC_SYSCLK_DIV1;
  RCC_ClkInitStruct.AHBCLKDivider = RCC_HCLK_DIV2;
  RCC_ClkInitStruct.APB3CLKDivider = RCC_APB3_DIV2;
  RCC_ClkInitStruct.APB1CLKDivider = RCC_APB1_DIV2;
  RCC_ClkInitStruct.APB2CLKDivider = RCC_APB2_DIV2;
  RCC_ClkInitStruct.APB4CLKDivider = RCC_APB4_DIV2;

  if (HAL_RCC_ClockConfig(&RCC_ClkInitStruct, FLASH_LATENCY_4) != HAL_OK)
  {
    Error_Handler();
  }
  HAL_RCC_MCOConfig(RCC_MCO1, RCC_MCO1SOURCE_HSE, RCC_MCODIV_1);
  /** Enables the Clock Security System
  */
  HAL_RCC_EnableCSS();
}

void PeriphCommonClock_Config(void)
{
  RCC_PeriphCLKInitTypeDef PeriphClkInitStruct = {0};

  /** Initializes the peripherals clock
  */
  PeriphClkInitStruct.PeriphClockSelection = RCC_PERIPHCLK_SAI1;
  PeriphClkInitStruct.PLL2.PLL2M = 25;
  PeriphClkInitStruct.PLL2.PLL2N = 512;
  PeriphClkInitStruct.PLL2.PLL2P = 125;
  PeriphClkInitStruct.PLL2.PLL2Q = 125;
  PeriphClkInitStruct.PLL2.PLL2R = 125;
  PeriphClkInitStruct.PLL2.PLL2RGE = RCC_PLL2VCIRANGE_0;
  PeriphClkInitStruct.PLL2.PLL2VCOSEL = RCC_PLL2VCOWIDE;
  PeriphClkInitStruct.PLL2.PLL2FRACN = 0;
  PeriphClkInitStruct.Sai1ClockSelection = RCC_SAI1CLKSOURCE_PLL2;
  if (HAL_RCCEx_PeriphCLKConfig(&PeriphClkInitStruct) != HAL_OK)
  {
    Error_Handler();
  }
}

static void MX_I2C1_Init(void)
{

  hi2c1.Instance = I2C1;
  hi2c1.Init.Timing = 0x307075B1;
  hi2c1.Init.OwnAddress1 = 0;
  hi2c1.Init.AddressingMode = I2C_ADDRESSINGMODE_7BIT;
  hi2c1.Init.DualAddressMode = I2C_DUALADDRESS_DISABLE;
  hi2c1.Init.OwnAddress2 = 0;
  hi2c1.Init.OwnAddress2Masks = I2C_OA2_NOMASK;
  hi2c1.Init.GeneralCallMode = I2C_GENERALCALL_DISABLE;
  hi2c1.Init.NoStretchMode = I2C_NOSTRETCH_DISABLE;
  if (HAL_I2C_Init(&hi2c1) != HAL_OK)
  {
    Error_Handler();
  }
  /** Configure Analogue filter
  */
  if (HAL_I2CEx_ConfigAnalogFilter(&hi2c1, I2C_ANALOGFILTER_ENABLE) != HAL_OK)
  {
    Error_Handler();
  }
  /** Configure Digital filter
  */
  if (HAL_I2CEx_ConfigDigitalFilter(&hi2c1, 0) != HAL_OK)
  {
    Error_Handler();
  }

}

static void MX_I2C2_Init(void)
{

  hi2c2.Instance = I2C2;
  hi2c2.Init.Timing = 0x307075B1;
  hi2c2.Init.OwnAddress1 = 0;
  hi2c2.Init.AddressingMode = I2C_ADDRESSINGMODE_7BIT;
  hi2c2.Init.DualAddressMode = I2C_DUALADDRESS_DISABLE;
  hi2c2.Init.OwnAddress2 = 0;
  hi2c2.Init.OwnAddress2Masks = I2C_OA2_NOMASK;
  hi2c2.Init.GeneralCallMode = I2C_GENERALCALL_DISABLE;
  hi2c2.Init.NoStretchMode = I2C_NOSTRETCH_DISABLE;
  if (HAL_I2C_Init(&hi2c2) != HAL_OK)
  {
    Error_Handler();
  }
  /** Configure Analogue filter
  */
  if (HAL_I2CEx_ConfigAnalogFilter(&hi2c2, I2C_ANALOGFILTER_ENABLE) != HAL_OK)
  {
    Error_Handler();
  }
  /** Configure Digital filter
  */
  if (HAL_I2CEx_ConfigDigitalFilter(&hi2c2, 0) != HAL_OK)
  {
    Error_Handler();
  }

}

static void MX_RNG_Init(void)
{

  hrng.Instance = RNG;
  hrng.Init.ClockErrorDetection = RNG_CED_ENABLE;
  if (HAL_RNG_Init(&hrng) != HAL_OK)
  {
    Error_Handler();
  }

}

static void MX_RTC_Init(void)
{

  RTC_TimeTypeDef sTime = {0};
  RTC_DateTypeDef sDate = {0};

  /** Initialize RTC Only
  */
  hrtc.Instance = RTC;
  hrtc.Init.HourFormat = RTC_HOURFORMAT_24;
  hrtc.Init.AsynchPrediv = 127;
  hrtc.Init.SynchPrediv = 255;
  hrtc.Init.OutPut = RTC_OUTPUT_DISABLE;
  hrtc.Init.OutPutPolarity = RTC_OUTPUT_POLARITY_HIGH;
  hrtc.Init.OutPutType = RTC_OUTPUT_TYPE_OPENDRAIN;
  hrtc.Init.OutPutRemap = RTC_OUTPUT_REMAP_NONE;
  if (HAL_RTC_Init(&hrtc) != HAL_OK)
  {
    Error_Handler();
  }

  /** Initialize RTC and set the Time and Date
  */
  sTime.Hours = 0x0;
  sTime.Minutes = 0x0;
  sTime.Seconds = 0x0;
  sTime.DayLightSaving = RTC_DAYLIGHTSAVING_NONE;
  sTime.StoreOperation = RTC_STOREOPERATION_RESET;
  if (HAL_RTC_SetTime(&hrtc, &sTime, RTC_FORMAT_BCD) != HAL_OK)
  {
    Error_Handler();
  }
  sDate.WeekDay = RTC_WEEKDAY_MONDAY;
  sDate.Month = RTC_MONTH_JANUARY;
  sDate.Date = 0x1;
  sDate.Year = 0x0;

  if (HAL_RTC_SetDate(&hrtc, &sDate, RTC_FORMAT_BCD) != HAL_OK)
  {
    Error_Handler();
  }

}

static void MX_SAI1_Init(void)
{

  hsai_BlockA1.Instance = SAI1_Block_A;
  hsai_BlockA1.Init.AudioMode = SAI_MODEMASTER_TX;
  hsai_BlockA1.Init.Synchro = SAI_ASYNCHRONOUS;
  hsai_BlockA1.Init.OutputDrive = SAI_OUTPUTDRIVE_DISABLE;
  hsai_BlockA1.Init.NoDivider = SAI_MASTERDIVIDER_ENABLE;
  hsai_BlockA1.Init.FIFOThreshold = SAI_FIFOTHRESHOLD_EMPTY;
  hsai_BlockA1.Init.AudioFrequency = SAI_AUDIO_FREQUENCY_16K;
  hsai_BlockA1.Init.SynchroExt = SAI_SYNCEXT_DISABLE;
  hsai_BlockA1.Init.MonoStereoMode = SAI_STEREOMODE;
  hsai_BlockA1.Init.CompandingMode = SAI_NOCOMPANDING;
  hsai_BlockA1.Init.TriState = SAI_OUTPUT_NOTRELEASED;
  if (HAL_SAI_InitProtocol(&hsai_BlockA1, SAI_I2S_STANDARD, SAI_PROTOCOL_DATASIZE_16BIT, 2) != HAL_OK)
  {
    Error_Handler();
  }
  hsai_BlockB1.Instance = SAI1_Block_B;
  hsai_BlockB1.Init.AudioMode = SAI_MODESLAVE_RX;
  hsai_BlockB1.Init.Synchro = SAI_SYNCHRONOUS;
  hsai_BlockB1.Init.OutputDrive = SAI_OUTPUTDRIVE_DISABLE;
  hsai_BlockB1.Init.FIFOThreshold = SAI_FIFOTHRESHOLD_EMPTY;
  hsai_BlockB1.Init.SynchroExt = SAI_SYNCEXT_DISABLE;
  hsai_BlockB1.Init.MonoStereoMode = SAI_STEREOMODE;
  hsai_BlockB1.Init.CompandingMode = SAI_NOCOMPANDING;
  hsai_BlockB1.Init.TriState = SAI_OUTPUT_NOTRELEASED;
  if (HAL_SAI_InitProtocol(&hsai_BlockB1, SAI_I2S_STANDARD, SAI_PROTOCOL_DATASIZE_16BIT, 2) != HAL_OK)
  {
    Error_Handler();
  }

}

static void MX_TIM3_Init(void)
{

  TIM_ClockConfigTypeDef sClockSourceConfig = {0};
  TIM_MasterConfigTypeDef sMasterConfig = {0};

  htim3.Instance = TIM3;
  htim3.Init.Prescaler = 0;
  htim3.Init.CounterMode = TIM_COUNTERMODE_UP;
  htim3.Init.Period = 15000;
  htim3.Init.ClockDivision = TIM_CLOCKDIVISION_DIV1;
  htim3.Init.AutoReloadPreload = TIM_AUTORELOAD_PRELOAD_DISABLE;
  if (HAL_TIM_Base_Init(&htim3) != HAL_OK)
  {
    Error_Handler();
  }
  sClockSourceConfig.ClockSource = TIM_CLOCKSOURCE_INTERNAL;
  if (HAL_TIM_ConfigClockSource(&htim3, &sClockSourceConfig) != HAL_OK)
  {
    Error_Handler();
  }
  sMasterConfig.MasterOutputTrigger = TIM_TRGO_RESET;
  sMasterConfig.MasterSlaveMode = TIM_MASTERSLAVEMODE_DISABLE;
  if (HAL_TIMEx_MasterConfigSynchronization(&htim3, &sMasterConfig) != HAL_OK)
  {
    Error_Handler();
  }

}

static void MX_UART7_Init(void)
{

  huart7.Instance = UART7;
  huart7.Init.BaudRate = 115200;
  huart7.Init.WordLength = UART_WORDLENGTH_8B;
  huart7.Init.StopBits = UART_STOPBITS_1;
  huart7.Init.Parity = UART_PARITY_NONE;
  huart7.Init.Mode = UART_MODE_TX_RX;
  huart7.Init.HwFlowCtl = UART_HWCONTROL_NONE;
  huart7.Init.OverSampling = UART_OVERSAMPLING_16;
  huart7.Init.OneBitSampling = UART_ONE_BIT_SAMPLE_DISABLE;
  huart7.Init.ClockPrescaler = UART_PRESCALER_DIV1;
  huart7.AdvancedInit.AdvFeatureInit = UART_ADVFEATURE_NO_INIT;
  if (HAL_UART_Init(&huart7) != HAL_OK)
  {
    Error_Handler();
  }
  if (HAL_UARTEx_SetTxFifoThreshold(&huart7, UART_TXFIFO_THRESHOLD_1_2) != HAL_OK)
  {
    Error_Handler();
  }
  if (HAL_UARTEx_SetRxFifoThreshold(&huart7, UART_RXFIFO_THRESHOLD_1_2) != HAL_OK)
  {
    Error_Handler();
  }
  if (HAL_UARTEx_EnableFifoMode(&huart7) != HAL_OK)
  {
    Error_Handler();
  }

}

static void MX_DMA_Init(void)
{

  /* DMA controller clock enable */
  __HAL_RCC_DMA1_CLK_ENABLE();
  __HAL_RCC_DMA2_CLK_ENABLE();

  /* DMA interrupt init */
  /* DMA1_Stream1_IRQn interrupt configuration */
  HAL_NVIC_SetPriority(DMA1_Stream1_IRQn, 5, 0);
  HAL_NVIC_EnableIRQ(DMA1_Stream1_IRQn);
  /* DMA1_Stream2_IRQn interrupt configuration */
  HAL_NVIC_SetPriority(DMA1_Stream2_IRQn, 5, 0);
  HAL_NVIC_EnableIRQ(DMA1_Stream2_IRQn);
  /* DMA1_Stream4_IRQn interrupt configuration */
  HAL_NVIC_SetPriority(DMA1_Stream4_IRQn, 5, 0);
  HAL_NVIC_EnableIRQ(DMA1_Stream4_IRQn);
  /* DMA2_Stream0_IRQn interrupt configuration */
  HAL_NVIC_SetPriority(DMA2_Stream0_IRQn, 5, 0);
  HAL_NVIC_EnableIRQ(DMA2_Stream0_IRQn);
  /* DMA2_Stream1_IRQn interrupt configuration */
  HAL_NVIC_SetPriority(DMA2_Stream1_IRQn, 5, 0);
  HAL_NVIC_EnableIRQ(DMA2_Stream1_IRQn);
  /* DMA2_Stream3_IRQn interrupt configuration */
  HAL_NVIC_SetPriority(DMA2_Stream3_IRQn, 5, 0);
  HAL_NVIC_EnableIRQ(DMA2_Stream3_IRQn);
  /* DMA2_Stream4_IRQn interrupt configuration */
  HAL_NVIC_SetPriority(DMA2_Stream4_IRQn, 5, 0);
  HAL_NVIC_EnableIRQ(DMA2_Stream4_IRQn);

}

/* FMC initialization function */
static void MX_FMC_Init(void)
{

  FMC_NORSRAM_TimingTypeDef Timing = {0};

  /** Perform the SRAM1 memory initialization sequence
  */
  hsram1.Instance = FMC_NORSRAM_DEVICE;
  hsram1.Extended = FMC_NORSRAM_EXTENDED_DEVICE;
  /* hsram1.Init */
  hsram1.Init.NSBank = FMC_NORSRAM_BANK1;
  hsram1.Init.DataAddressMux = FMC_DATA_ADDRESS_MUX_DISABLE;
  hsram1.Init.MemoryType = FMC_MEMORY_TYPE_SRAM;
  hsram1.Init.MemoryDataWidth = FMC_NORSRAM_MEM_BUS_WIDTH_32;
  hsram1.Init.BurstAccessMode = FMC_BURST_ACCESS_MODE_DISABLE;
  hsram1.Init.WaitSignalPolarity = FMC_WAIT_SIGNAL_POLARITY_LOW;
  hsram1.Init.WaitSignalActive = FMC_WAIT_TIMING_BEFORE_WS;
  hsram1.Init.WriteOperation = FMC_WRITE_OPERATION_DISABLE;
  hsram1.Init.WaitSignal = FMC_WAIT_SIGNAL_DISABLE;
  hsram1.Init.ExtendedMode = FMC_EXTENDED_MODE_DISABLE;
  hsram1.Init.AsynchronousWait = FMC_ASYNCHRONOUS_WAIT_DISABLE;
  hsram1.Init.WriteBurst = FMC_WRITE_BURST_DISABLE;
  hsram1.Init.ContinuousClock = FMC_CONTINUOUS_CLOCK_SYNC_ONLY;
  hsram1.Init.WriteFifo = FMC_WRITE_FIFO_ENABLE;
  hsram1.Init.PageSize = FMC_PAGE_SIZE_NONE;
  /* Timing */
  Timing.AddressSetupTime = 15;
  Timing.AddressHoldTime = 15;
  Timing.DataSetupTime = 255;
  Timing.BusTurnAroundDuration = 15;
  Timing.CLKDivision = 16;
  Timing.DataLatency = 17;
  Timing.AccessMode = FMC_ACCESS_MODE_A;
  /* ExtTiming */

  if (HAL_SRAM_Init(&hsram1, &Timing, NULL) != HAL_OK)
  {
    Error_Handler( );
  }

}

static void MX_GPIO_Init(void)
{
  GPIO_InitTypeDef GPIO_InitStruct = {0};

  /* GPIO Ports Clock Enable */
  __HAL_RCC_GPIOE_CLK_ENABLE();
  __HAL_RCC_GPIOI_CLK_ENABLE();
  __HAL_RCC_GPIOF_CLK_ENABLE();
  __HAL_RCC_GPIOH_CLK_ENABLE();
  __HAL_RCC_GPIOC_CLK_ENABLE();
  __HAL_RCC_GPIOA_CLK_ENABLE();
  __HAL_RCC_GPIOB_CLK_ENABLE();
  __HAL_RCC_GPIOG_CLK_ENABLE();
  __HAL_RCC_GPIOD_CLK_ENABLE();

  /*Configure GPIO pin Output Level */
  HAL_GPIO_WritePin(GPIOB, POW_DOWN_Pin|TEST_LED_Pin, GPIO_PIN_SET);

  /*Configure GPIO pin Output Level */
  HAL_GPIO_WritePin(GPIOG, L4_Pin|L5_Pin|L6_Pin, GPIO_PIN_RESET);

  /*Configure GPIO pin Output Level */
  HAL_GPIO_WritePin(GPIOA, RELE1_UPR_Pin|AMP_UPR_Pin, GPIO_PIN_RESET);

  /*Configure GPIO pin Output Level */
  HAL_GPIO_WritePin(GPIOC, L1_Pin|L2_Pin|L3_Pin, GPIO_PIN_RESET);

  /*Configure GPIO pins : POW_DOWN_Pin TEST_LED_Pin */
  GPIO_InitStruct.Pin = POW_DOWN_Pin|TEST_LED_Pin;
  GPIO_InitStruct.Mode = GPIO_MODE_OUTPUT_PP;
  GPIO_InitStruct.Pull = GPIO_NOPULL;
  GPIO_InitStruct.Speed = GPIO_SPEED_FREQ_LOW;
  HAL_GPIO_Init(GPIOB, &GPIO_InitStruct);

  /*Configure GPIO pins : L4_Pin L5_Pin L6_Pin */
  GPIO_InitStruct.Pin = L4_Pin|L5_Pin|L6_Pin;
  GPIO_InitStruct.Mode = GPIO_MODE_OUTPUT_PP;
  GPIO_InitStruct.Pull = GPIO_NOPULL;
  GPIO_InitStruct.Speed = GPIO_SPEED_FREQ_LOW;
  HAL_GPIO_Init(GPIOG, &GPIO_InitStruct);

  /*Configure GPIO pin : PA8 */
  GPIO_InitStruct.Pin = GPIO_PIN_8;
  GPIO_InitStruct.Mode = GPIO_MODE_AF_PP;
  GPIO_InitStruct.Pull = GPIO_PULLUP;
  GPIO_InitStruct.Speed = GPIO_SPEED_FREQ_LOW;
  GPIO_InitStruct.Alternate = GPIO_AF0_MCO;
  HAL_GPIO_Init(GPIOA, &GPIO_InitStruct);

  /*Configure GPIO pins : TANG_UPR_Pin PEDAL_UPR_Pin */
  GPIO_InitStruct.Pin = TANG_UPR_Pin|PEDAL_UPR_Pin;
  GPIO_InitStruct.Mode = GPIO_MODE_INPUT;
  GPIO_InitStruct.Pull = GPIO_NOPULL;
  HAL_GPIO_Init(GPIOA, &GPIO_InitStruct);

  /*Configure GPIO pins : RELE1_UPR_Pin AMP_UPR_Pin */
  GPIO_InitStruct.Pin = RELE1_UPR_Pin|AMP_UPR_Pin;
  GPIO_InitStruct.Mode = GPIO_MODE_OUTPUT_PP;
  GPIO_InitStruct.Pull = GPIO_NOPULL;
  GPIO_InitStruct.Speed = GPIO_SPEED_FREQ_LOW;
  HAL_GPIO_Init(GPIOA, &GPIO_InitStruct);

  /*Configure GPIO pins : L1_Pin L2_Pin L3_Pin */
  GPIO_InitStruct.Pin = L1_Pin|L2_Pin|L3_Pin;
  GPIO_InitStruct.Mode = GPIO_MODE_OUTPUT_PP;
  GPIO_InitStruct.Pull = GPIO_NOPULL;
  GPIO_InitStruct.Speed = GPIO_SPEED_FREQ_LOW;
  HAL_GPIO_Init(GPIOC, &GPIO_InitStruct);

  /*Configure GPIO pins : K1_Pin K2_Pin K3_Pin K4_Pin
                           K5_Pin K6_Pin */
  GPIO_InitStruct.Pin = K1_Pin|K2_Pin|K3_Pin|K4_Pin
                          |K5_Pin|K6_Pin;
  GPIO_InitStruct.Mode = GPIO_MODE_INPUT;
  GPIO_InitStruct.Pull = GPIO_NOPULL;
  HAL_GPIO_Init(GPIOG, &GPIO_InitStruct);

  /*Configure GPIO pin : TEST_BUT_Pin */
  GPIO_InitStruct.Pin = TEST_BUT_Pin;
  GPIO_InitStruct.Mode = GPIO_MODE_INPUT;
  GPIO_InitStruct.Pull = GPIO_NOPULL;
  HAL_GPIO_Init(TEST_BUT_GPIO_Port, &GPIO_InitStruct);

}

void StartDefaultTask(void const * argument)
{
  /* init code for LWIP */
  MX_LWIP_Init();
  /* USER CODE BEGIN 5 */

  char msgUart7[] = "\r------- StartDefaultTask ----------\n\r";
  RS232_write_c(msgUart7, sizeof (msgUart7));

  if (DP83848.Is_Initialized) {
    RS232_write_c("\rDP83848.Is_Initialized\r\n", sizeof ("\rDP83848.Is_Initialized\r\n"));
  } else {
    RS232_write_c("\rDP83848.No_Initialized\r\n", sizeof ("\rDP83848.No_Initialized\r\n"));
  }

  for(;;)
  {
      ethernetif_input(&gnetif);
      sys_check_timeouts();
      Ethernet_Link_Periodic_Handle(&gnetif);

    osDelay(1);
  }
  /* USER CODE END 5 */
}

void Test_Led_Task_(void const * argument)
{
  /* USER CODE BEGIN Test_Led_Task_ */

    (void)argument;
    osDelay (10);
    char msgUart7[] = "\r------- StartTest_Led_Task --------\n\r";
//    HAL_UART_Transmit_IT (&huart7,(uint8_t*)msgUart7, sizeof (msgUart7));
    RS232_write_c(msgUart7, sizeof (msgUart7));
    uint8_t reset = 1;
    uint32_t tickstart = HAL_GetTick();
    uint32_t timeSet = 1;
    uint32_t timeReset = 2000;

  /* Infinite loop */
  for(;;)
  {
      if(reset == 1)
      {
          if (HAL_GetTick() > tickstart + timeReset)
          {
              HAL_GPIO_WritePin(GPIOB, TEST_LED_Pin, GPIO_PIN_SET);
              reset = 0;
              tickstart = HAL_GetTick();
              sprintf(msgUart7,"\r%s %d\n\r", "------- LED_Blink -------------", (int)osKernelSysTick());
//              HAL_UART_Transmit_IT (&huart7,(uint8_t*)msgUart7, sizeof(msgUart7));
          }
      }
      if(reset == 0)
      {
          if (HAL_GetTick() > tickstart + timeSet)
          {
              HAL_GPIO_WritePin(GPIOB, TEST_LED_Pin, GPIO_PIN_RESET);
              reset = 1;
              tickstart = HAL_GetTick();
          }
      }
      osDelay (1);
  }
  vTaskDelete(NULL);

  /* USER CODE END Test_Led_Task_ */
}

void LEDS_1_2_3_TEST_(void const * argument)
{
  /* USER CODE BEGIN LEDS_1_2_3_TEST_ */
  (void)argument;
  osDelay (20);
  char msgUart7[50];
  memset(msgUart7,' ',50);
  sprintf(msgUart7,"\r%s", "------- StartLEDS_1_2_3_TEST ------\n\r");
//  HAL_UART_Transmit_IT (&huart7,(uint8_t*)msgUart7, sizeof (msgUart7));
  RS232_write_c(msgUart7, sizeof (msgUart7));
  uint8_t reset = 1;
  uint32_t tickstart = HAL_GetTick();
  uint32_t timeSet = 1;
  uint32_t timeReset = 3000;

  /* Infinite loop */
      for(;;)
  {
      if(reset == 1)
      {
          if (HAL_GetTick() > tickstart + timeReset)
          {
              HAL_GPIO_WritePin(GPIOC, L1_Pin|L2_Pin|L3_Pin, GPIO_PIN_SET);
              reset = 0;
              tickstart = HAL_GetTick();
              sprintf(msgUart7,"\r%s %d\n\r", "------- LEDS_1_2_3_Blink ------", (int)osKernelSysTick());
//              HAL_UART_Transmit_IT (&huart7,(uint8_t*)msgUart7, sizeof(msgUart7));
          }
      }
      if(reset == 0)
      {
          if (HAL_GetTick() > tickstart + timeSet)
          {
              HAL_GPIO_WritePin(GPIOC, L1_Pin|L2_Pin|L3_Pin, GPIO_PIN_RESET);
              reset = 1;
              tickstart = HAL_GetTick();
          }
      }
      osDelay (1);
  }
  vTaskDelete(NULL);

  /* USER CODE END LEDS_1_2_3_TEST_ */
}

void LEDS_4_5_6_TEST_(void const * argument)
{
  /* USER CODE BEGIN LEDS_4_5_6_TEST_ */

    (void)argument;
    osDelay (30);
    char msgUart7[50];
    memset(msgUart7,' ',50);
    sprintf(msgUart7,"\r%s", "------- StartLEDS_4_5_6_TEST ------\n\r");
//    HAL_UART_Transmit_IT (&huart7,(uint8_t*)msgUart7, sizeof (msgUart7));
    RS232_write_c(msgUart7, sizeof (msgUart7));
    uint8_t reset = 1;
    uint32_t tickstart = HAL_GetTick();
    uint32_t timeSet = 1;
    uint32_t timeReset = 4000;

    /* Infinite loop */
    for(;;)
    {
        if(reset == 1)
        {
            if (HAL_GetTick() > tickstart + timeReset)
            {
                HAL_GPIO_WritePin(GPIOG, L4_Pin|L5_Pin|L6_Pin, GPIO_PIN_SET);
                reset = 0;
                tickstart = HAL_GetTick();
                sprintf(msgUart7,"\r%s %d\n\r", "------- LEDS 4 5 6 Blink ------", (int)osKernelSysTick());
//                HAL_UART_Transmit_IT (&huart7,(uint8_t*)msgUart7, sizeof(msgUart7));
            }
        }
        if(reset == 0)
        {
            if (HAL_GetTick() > tickstart + timeSet)
            {
                HAL_GPIO_WritePin(GPIOG, L4_Pin|L5_Pin|L6_Pin, GPIO_PIN_RESET);
                reset = 1;
                tickstart = HAL_GetTick();
            }
        }
        osDelay (1);
    }
    vTaskDelete(NULL);

  /* USER CODE END LEDS_4_5_6_TEST_ */
}

void KEYS_TEST_TASK_(void const * argument)
{
  /* USER CODE BEGIN KEYS_TEST_TASK_ */
    (void)argument;
    osDelay (40);
    char msgUart7[] = "\r------- StartKEYS_TEST_TASK -------\n\r";
//    HAL_UART_Transmit_IT (&huart7,(uint8_t*)msgUart7, sizeof (msgUart7));
    RS232_write_c(msgUart7, sizeof (msgUart7));
  /* Infinite loop */
  for(;;)
  {
    osDelay(1);
  }
  /* USER CODE END KEYS_TEST_TASK_ */
}

void EEPROM_Tests_(void const * argument)
{
  /* USER CODE BEGIN EEPROM_Tests_ */
    (void)argument;
    osDelay (50);

    char msgUart7[] = "\r------- StartEEPROM_Tests_TASK ----\n\r";
//    HAL_UART_Transmit_IT (&huart7,(uint8_t*)msgUart7, sizeof (msgUart7));
    RS232_write_c(msgUart7, sizeof (msgUart7));

    simpleEEPROM_test();
    osDelay(100);
    simpleEEPROM_test2();
    FS_test();
  /* Infinite loop */
  for(;;)
  {
    osDelay(1);
  }
  /* USER CODE END EEPROM_Tests_ */
}

/* MPU Configuration */

void MPU_Config(void)
{
  MPU_Region_InitTypeDef MPU_InitStruct = {0};

  /* Disables the MPU */
  HAL_MPU_Disable();
  /** Initializes and configures the Region and the memory to be protected
  */
  MPU_InitStruct.Enable = MPU_REGION_ENABLE;
  MPU_InitStruct.Number = MPU_REGION_NUMBER0;
  MPU_InitStruct.BaseAddress = 30000000;
  MPU_InitStruct.Size = MPU_REGION_SIZE_256KB;
  MPU_InitStruct.SubRegionDisable = 0x0;
  MPU_InitStruct.TypeExtField = MPU_TEX_LEVEL1;
  MPU_InitStruct.AccessPermission = MPU_REGION_FULL_ACCESS;
  MPU_InitStruct.DisableExec = MPU_INSTRUCTION_ACCESS_DISABLE;
  MPU_InitStruct.IsShareable = MPU_ACCESS_NOT_SHAREABLE;
  MPU_InitStruct.IsCacheable = MPU_ACCESS_NOT_CACHEABLE;
  MPU_InitStruct.IsBufferable = MPU_ACCESS_NOT_BUFFERABLE;

  HAL_MPU_ConfigRegion(&MPU_InitStruct);
  /** Initializes and configures the Region and the memory to be protected
  */
  MPU_InitStruct.Number = MPU_REGION_NUMBER1;
  MPU_InitStruct.BaseAddress = 0x30000000;
  MPU_InitStruct.Size = MPU_REGION_SIZE_256B;
  MPU_InitStruct.TypeExtField = MPU_TEX_LEVEL0;
  MPU_InitStruct.IsShareable = MPU_ACCESS_SHAREABLE;
  MPU_InitStruct.IsBufferable = MPU_ACCESS_BUFFERABLE;

  HAL_MPU_ConfigRegion(&MPU_InitStruct);
  /** Initializes and configures the Region and the memory to be protected
  */
  MPU_InitStruct.Number = MPU_REGION_NUMBER2;
  MPU_InitStruct.BaseAddress = 0x30040000;
  MPU_InitStruct.Size = MPU_REGION_SIZE_32KB;
  MPU_InitStruct.TypeExtField = MPU_TEX_LEVEL1;
  MPU_InitStruct.IsShareable = MPU_ACCESS_NOT_SHAREABLE;
  MPU_InitStruct.IsBufferable = MPU_ACCESS_NOT_BUFFERABLE;

  HAL_MPU_ConfigRegion(&MPU_InitStruct);
  /* Enables the MPU */
  HAL_MPU_Enable(MPU_PRIVILEGED_DEFAULT);

}

void HAL_TIM_PeriodElapsedCallback(TIM_HandleTypeDef *htim)
{
  if (htim->Instance == TIM1) {
    HAL_IncTick();
  }
}

void Error_Handler(void)
{
  __disable_irq();
  while (1)
  {
  }
}
